# DMM register map
Vendor: Texas Instruments
Peripheral module from a debugger description file (folder am574x).
Registers are 32-bit, access not given, reset values left out (the file's numbers can be read two ways) unless marked. A register's access mark holds for its fields unless they carry their own. Offsets are as the file gives them; lines under a group give offsets from that group; [hi:lo] are bit positions; {n}, {i} and the like mark numbered series; 'fields as' and 'values as' point back to an identical list; <NAME> marks a mode.

## DMM
0x00 DMM_REVISION ro — DMM revision number
  [31:0] REVISION — Revision number
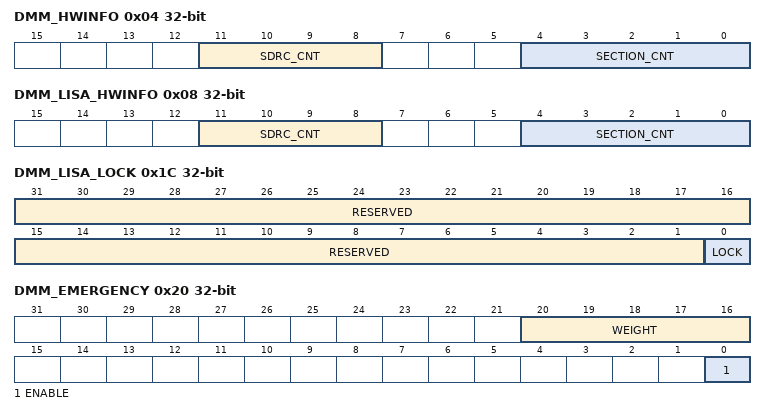
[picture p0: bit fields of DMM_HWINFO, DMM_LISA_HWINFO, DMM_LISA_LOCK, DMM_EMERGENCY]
0x04 DMM_HWINFO ro — DMM hardware configuration
  [11:8] SDRC_CNT — Number of attached SDRAM controllers
  [4:0] SECTION_CNT — Number of DMM sections
0x08 DMM_LISA_HWINFO ro — DMM hardware configuration for LISA
  fields as DMM_HWINFO
0x10 DMM_SYSCONFIG — DMM clock management configuration
  [3:2] IDLE_MODE rw — Configuration of the local target state management mode.
    0=FORCE_IDLE (Force-idle mode: local target's idle state follows (acknowledges) the system's idle requests unconditionally, that is, regardless of the IP module's internal requirements. Backup mode, for debug only.); 1=NO_IDLE (No-idle mode: local target never enters idle state. Backup mode, for debug only.); 2=SMART (Smart-idle mode: local target's idle state eventually follows (acknowledges) the system's idle requests, depending on the IP module's internal requirements. IP module shall not generate (IRQ- or DMA-request-related) wake-up events.)
0x1C DMM_LISA_LOCK access per field — DMM memory mapping lock
  [31:1] RESERVED ro — Should be written as 0
  [0] LOCK rw — DMM lock map
    0=UNLOCKED (No effect (clear on reset only)); 0=UNLOCKED; 1=LOCKED; 1=LOCKED (Locking registers)
0x20 DMM_EMERGENCY access per field — DMM memory mapping register
  [20:16] WEIGHT rw — Weight for the LISA arbitration when any bit of the vector Mflag[63:0] is set.The recommendation is to set this field to 0x8 with ENABLE =1, after reset. .
  [0] ENABLE rw — 0: Emergency feature is disabled.The recommendation is to enable the feature (=1) after reset. enum=UNLOCKED .
    1=UNLOCKED (Enable the emergency feature. LISA arbitration priority is higher for the initiator that set Mflag input of this initiator.)
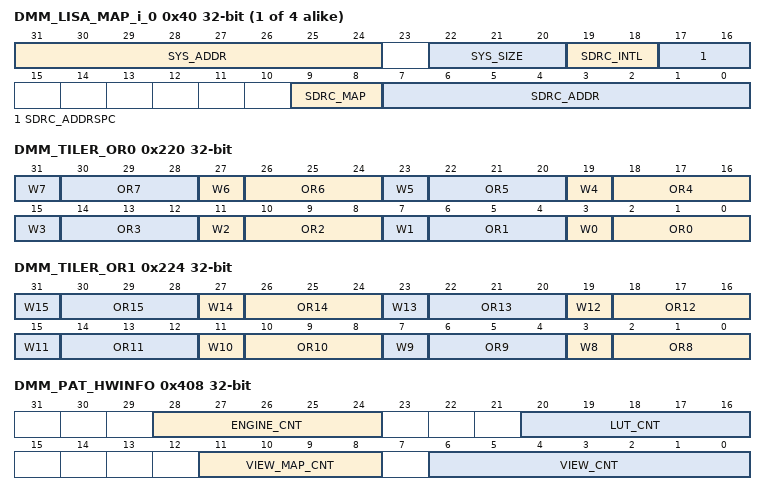
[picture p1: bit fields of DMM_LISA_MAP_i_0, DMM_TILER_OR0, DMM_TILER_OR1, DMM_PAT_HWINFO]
{0x40+4i} DMM_LISA_MAP_i_{i} (i=0..3) — DMM memory mapping register
  [31:24] SYS_ADDR rw — DMM system section address MSB for view mapping i
  [22:20] SYS_SIZE rw — DMM system section size for view mapping i
    0=16-MiB_section; 1=32-MiB_section; 2=64-MiB_section; 3=128-MiB_section; 4=256-MiB_section; 5=512-MiB_section; 6=1-GiB_section; 7=2-GiB_section
  [19:18] SDRC_INTL rw — SDRAM controller interleaving mode 0x0: No interleaving 0x1: 128-byte interleaving 0x2: 256-byte interleaving 0x3: 512-byte interleaving The 128-/256-/512-byte interleaving applies only to nontiled regions. If accesses are made to tiled regions, interleaving is forced to 1kiB. SDRC_INTL is don't care if SDRC_MAP is not 0x3 (no interleaving).
  [17:16] SDRC_ADDRSPC rw — SDRAM controller address space for view mapping i
  [9:8] SDRC_MAP rw — SDRAM controller mapping for view mapping i 0x0: Unmapped 0x1: Mapped on EMIF1 only (not interleaved) 0x2: Mapped on EMIF2 only (not interleaved) 0x3: Mapped on EMIF1 and EMIF2 (interleaved) To enable interleaving, SDRC_MAP must be 0x3 and SDRC_INTL must be a nonzero value.
  [7:0] SDRC_ADDR rw — SDRAM controller address MSB for view mapping i
0x208 DMM_TILER_HWINFO ro — DMM hardware configuration for TILER
  [6:0] OR_CNT — Number of TILER orientation entries
    4=OR_CNT_4_r (Four orientation entries); 32=OR_CNT_32_r (Thirty-two orientation entries); 64=OR_CNT_64_r (Sixty-four orientation entries); 2=OR_CNT_2_r (Two orientation entries); 1=OR_CNT_1_r (One orientation entry); 8=OR_CNT_8_r (Eight orientation entries); 16=OR_CNT_16_r (Sixteen orientation entries)
0x220 DMM_TILER_OR0 rw — DMM TILER orientation (initiators 0 to 7)
  [4n+3] W{n} (n=0..7) — Write-enable for OR{n} bit field
    0=OR{n}_field_is_unchanged; 1=OR{n}_field_is_updated
  [4n+2:4n] OR{n} (n=0..7) — Orientation for initiator {n}
0x224 DMM_TILER_OR1 rw — DMM TILER orientation (initiators 8 to 15)
  [4n-29] W{n} (n=8..15) — Write-enable for OR{n} bit field
    0=OR{n}_field_is_unchanged; 1=OR{n}_field_is_updated
  [4n-30:4n-32] OR{n} (n=8..15) — Orientation for initiator {n}
0x408 DMM_PAT_HWINFO ro — DMM hardware configuration for PAT
  [28:24] ENGINE_CNT — Number of PAT refill engines
  [20:16] LUT_CNT — Number of PAT LUT for page-grained physical address translation
  [11:8] VIEW_MAP_CNT — Number of internal PAT view mappings.
    1=VIEW_MAP_CNT_1_r (One view map); 2=VIEW_MAP_CNT_2_r (Two view maps); 4=VIEW_MAP_CNT_4_r (Four view maps); 8=VIEW_MAP_CNT_8_r (Eight view maps)
  [6:0] VIEW_CNT — Number of PAT view entries
    1=VIEW_CNT_1_r (One view entry); 2=VIEW_CNT_2_r (Two view entries); 4=VIEW_CNT_4_r (Four view entries); 8=VIEW_CNT_8_r (Eight view entries); 16=VIEW_CNT_16_r (Sixteen view entries); 32=VIEW_CNT_32_r (Thirty-two view entries); 64=VIEW_CNT_64_r (Sixty-four view entries)
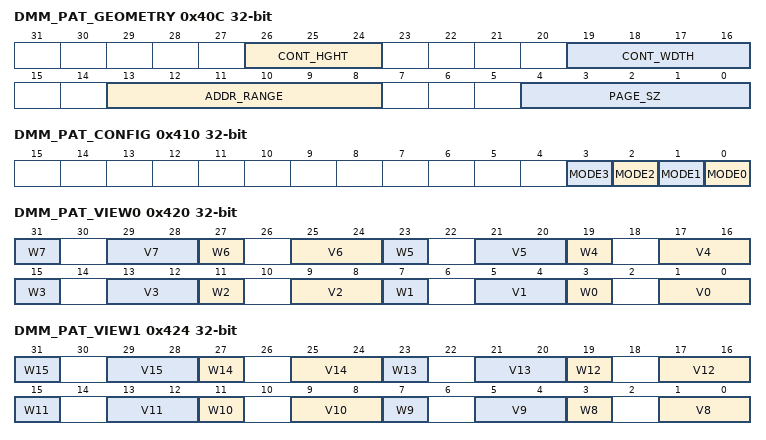
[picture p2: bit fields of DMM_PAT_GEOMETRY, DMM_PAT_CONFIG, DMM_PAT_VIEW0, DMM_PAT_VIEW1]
0x40C DMM_PAT_GEOMETRY ro — PAT geometry-related settings
  [26:24] CONT_HGHT — Container height in pages
  [19:16] CONT_WDTH — Container width in pages
    2=CONT_WDTH_2_r (Container width of 64 pages); 4=CONT_WDTH_4_r (Container width of 128 pages); 8=CONT_WDTH_8_r (Container width of 256 pages)
  [13:8] ADDR_RANGE — PAT output physical address range
    1=128MB (128-MiB range); 2=256MB (256-MiB range); 4=512MB (512-MiB range); 8=1GB (1-GiB range); 16=2GB (2-GiB range); 32=4GB (4-GiB range)
  [4:0] PAGE_SZ — Page size in 4-kiB granularity
    1=4KB (4-kiB page); 4=16KB (16-kiB page); 16=64KB (64-kiB page)
0x410 DMM_PAT_CONFIG access per field — This is the PAT configuration register aimed at defining the major PAT configuration of each refill engine.
  [all] fields
    0=PROG (Normal mode); 1=BYPASS (Direct LUT access)
  [n] MODE{n} rw (n=0..3) — Mode of refill engine {n}
0x420 DMM_PAT_VIEW0 — DMM PAT View register (initiators 0 to 7)
  [4n+3] W{n} rw (n=0..7) — Write-enable for V{n} bit field
    0=V{n}_field_is_unchanged; 1=V{n}_field_is_updated
  [4n+1:4n] V{n} rw (n=0..7) — PAT view for initiator {n}
0x424 DMM_PAT_VIEW1 — DMM PAT view register (initiators 8 to 15)
  [4n-29] W{n} rw (n=8..15) — Write-enable for V{n} bit field
    0=V{n}_field_is_unchanged; 1=V{n}_field_is_updated
  [4n-31:4n-32] V{n} rw (n=8..15) — PAT view for initiator {n}
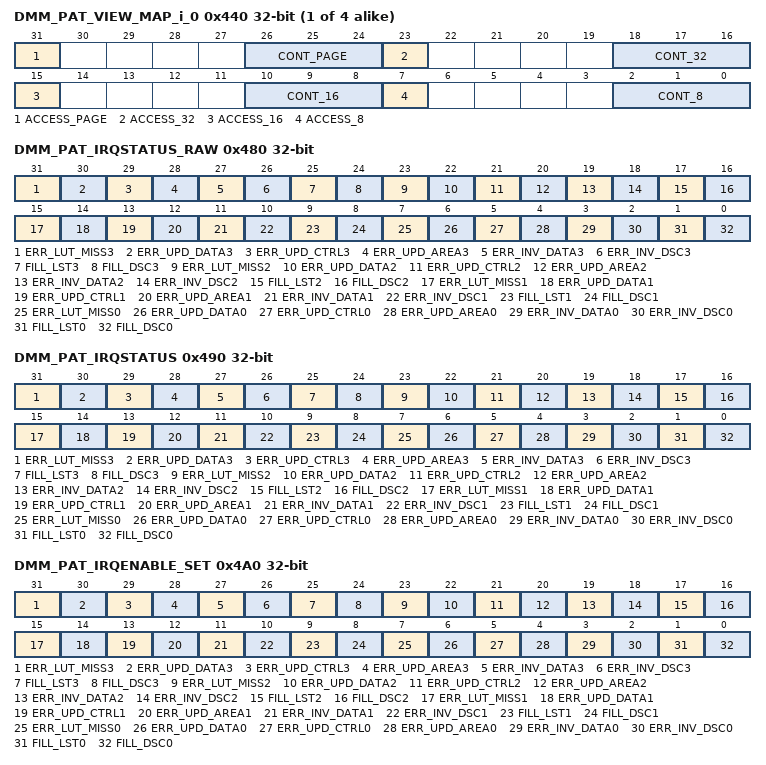
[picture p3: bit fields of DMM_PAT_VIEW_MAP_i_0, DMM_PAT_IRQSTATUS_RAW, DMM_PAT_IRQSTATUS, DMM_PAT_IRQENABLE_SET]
{0x440+4i} DMM_PAT_VIEW_MAP_i_{i} (i=0..3) — PAT view mapping register
  [31] ACCESS_PAGE rw — Kind of access for this page mode container in view mapping i
    0=DIRECT (Direct access, container base address given in CONT_PAGE); 1=LUT (indirect access through the LUT indexed by CONT_PAGE)
  [26:24] CONT_PAGE rw — Container for page mode in view mapping i
  [23] ACCESS_32 rw — Kind of access for this 32-bit mode container in view mapping i
    0=DIRECT (Direct access, container base address given in CONT_32); 1=LUT (indirect access through the LUT indexed by CONT_32)
  [18:16] CONT_32 rw — Container for 32-bit mode in view mapping i
  [15] ACCESS_16 rw — Kind of access for this 16-bit mode container in view mapping i
    0=DIRECT (Direct access, container base address given in CONT_16); 1=LUT (indirect access through the LUT indexed by CONT_16)
  [10:8] CONT_16 rw — Container for 16-bit mode in view mapping i
  [7] ACCESS_8 rw — Kind of access for this 8-bit mode container in view mapping i
    0=DIRECT (Direct access, container base address given in CONT_8); 1=LUT (indirect access through the LUT indexed by CONT_8)
  [2:0] CONT_8 rw — Container for 8-bit mode in view mapping i
0x460 DMM_PAT_VIEW_MAP_BASE — Base address of all view mappings
  [31] BASE_ADDR rw — MSB of the PAT view mapping base address
0x478 DMM_PAT_IRQ_EOI access per field — PAT end of interrupt
  [0] EOI rw — End of PAT interrupt
    0=ACK (Acknowledge the PAT interrupts)
0x480 DMM_PAT_IRQSTATUS_RAW — Per-event raw interrupt status vector. Raw status is set even if the related event is not enabled. Write 1 to set the (raw) status, mostly for debug. n = 0 for the first interrupt status raw register, n = 1 for the second interrupt status raw register.
  [31] ERR_LUT_MISS3 — Access to a yet-to-be-refilled area event in area 4.n+3 (access RW W1toSet)
    0=KEEP (Keep current error event.); 1=SET (Set error event.); 1=HAPPEN (Error event happened.); 0=NONE (No such error event)
  [30] ERR_UPD_DATA3 — Data register update whilst refilling error event in area 4.n+3 (access RW W1toSet)
    values as ERR_LUT_MISS3
  [29] ERR_UPD_CTRL3 — Control register update whilst refilling error event in area 4.n+3 (access RW W1toSet)
    values as ERR_LUT_MISS3
  [28] ERR_UPD_AREA3 — Area register update whilst refilling error event in area 4.n+3 (access RW W1toSet)
    values as ERR_LUT_MISS3
  [27] ERR_INV_DATA3 — Invalid entry-table pointer error event in area 4.n+3 (access RW W1toSet)
    0=KEEP (Keep current error event.); 1=SET (Set error event.); 1=HAPPEN (Error event happened.); 0=NONE (No such error event.)
  [26] ERR_INV_DSC3 — Invalid descriptor pointer error event in area 4.n+3 (access RW W1toSet)
    values as ERR_LUT_MISS3
  [25] FILL_LST3 — End of refill event for the last descriptor in area 4.n+3 (access RW W1toSet)
    0=KEEP (Keep area 3 refill done event.); 1=SET (Set area 3 refill done event.); 1=DONE (Area 3 is refilled.); 0=NOT (Area 3 is yet-to-be refilled.)
  [24] FILL_DSC3 — End of refill event for any descriptor in area 4.n+3 (access RW W1toSet)
    values as FILL_LST3
  [23] ERR_LUT_MISS2 — Access to a yet-to-be-refilled area event in area 4.n+2 (access RW W1toSet)
    values as ERR_LUT_MISS3
  [22] ERR_UPD_DATA2 — Data register update whilst refilling error event in area 4.n+2 (access RW W1toSet)
    values as ERR_LUT_MISS3
  [21] ERR_UPD_CTRL2 — Control register update whilst refilling error event in area 4.n+2 (access RW W1toSet)
    values as ERR_LUT_MISS3
  [20] ERR_UPD_AREA2 — Area register update whilst refilling error event in area 4.n+2 (access RW W1toSet)
    values as ERR_LUT_MISS3
  [19] ERR_INV_DATA2 — Invalid entry-table pointer error event in area 4.n+2 (access RW W1toSet)
    values as ERR_LUT_MISS3
  [18] ERR_INV_DSC2 — Invalid descriptor pointer error event in area 4.n+2 (access RW W1toSet)
    values as ERR_LUT_MISS3
  [17] FILL_LST2 — End of refill event for the last descriptor in area 4.n+2 (access RW W1toSet)
    0=KEEP (Keep area 2 refill done event.); 1=SET (Set area 2 refill done event.); 1=DONE (Area 2 is refilled.); 0=NOT (Area 2 is yet-to-be refilled.)
  [16] FILL_DSC2 — End of refill event for any descriptor in area 4.n+2 (access RW W1toSet)
    values as FILL_LST2
  [15] ERR_LUT_MISS1 — Access to a yet-to-be-refilled area event in area 4.n+1 (access RW W1toSet)
    values as ERR_LUT_MISS3
  [14] ERR_UPD_DATA1 — Data register update whilst refilling error event in area 4.n+1 (access RW W1toSet)
    values as ERR_LUT_MISS3
  [13] ERR_UPD_CTRL1 — Control register update whilst refilling error event in area 4.n+1 (access RW W1toSet)
    values as ERR_LUT_MISS3
  [12] ERR_UPD_AREA1 — Area register update whilst refilling error event in area 4.n+1 (access RW W1toSet)
    values as ERR_LUT_MISS3
  [11] ERR_INV_DATA1 — Invalid entry-table pointer error event in area 4.n+1 (access RW W1toSet)
    values as ERR_LUT_MISS3
  [10] ERR_INV_DSC1 — Invalid descriptor pointer error event in area 4.n+1 (access RW W1toSet)
    values as ERR_LUT_MISS3
  [9] FILL_LST1 — End of refill event for the last descriptor in area 4.n+1 (access RW W1toSet)
    0=KEEP (Keep area 1 refill done event.); 1=SET (Set area 1 refill done event.); 1=DONE (Area 1 is refilled.); 0=NOT (Area 1 is yet-to-be refilled.)
  [8] FILL_DSC1 — End of refill event for any descriptor in area 4.n+1 (access RW W1toSet)
    values as FILL_LST1
  [7] ERR_LUT_MISS0 — Access to a yet-to-be-refilled area event in area 4.n (access RW W1toSet)
    values as ERR_LUT_MISS3
  [6] ERR_UPD_DATA0 — Data register update whilst refilling error event in area 4.n (access RW W1toSet)
    values as ERR_LUT_MISS3
  [5] ERR_UPD_CTRL0 — Control register update whilst refilling error event in area 4.n (access RW W1toSet)
    values as ERR_LUT_MISS3
  [4] ERR_UPD_AREA0 — Area register update whilst refilling error event in area 4.n (access RW W1toSet)
    values as ERR_LUT_MISS3
  [3] ERR_INV_DATA0 — Invalid entry-table pointer error event in area 4.n (access RW W1toSet)
    values as ERR_LUT_MISS3
  [2] ERR_INV_DSC0 — Invalid descriptor pointer error event in area 4.n (access RW W1toSet)
    values as ERR_LUT_MISS3
  [1] FILL_LST0 — End of refill event for the last descriptor in area 4.n (access RW W1toSet)
    0=KEEP (Keep area 0 refill done event.); 1=SET (Set area 0 refill done event.); 1=DONE (Area 0 is refilled.); 0=NOT (Area 0 is yet-to-be refilled.)
  [0] FILL_DSC0 — End of refill event for any descriptor in area 4.n (access RW W1toSet)
    values as FILL_LST0
0x490 DMM_PAT_IRQSTATUS — Per-event 'enabled' interrupt status vector. Enabled status is not set unless the event is enabled. Write 1 to clear the status after interrupt has been serviced (raw status gets cleared, that is, even if not enabled). n = 0 for the first interrupt status register, n = 1 for the second interrupt status register.
  [31] ERR_LUT_MISS3 — Access to a yet-to-be-refilled area event in area 4.n+3 (access RW W1toClr)
    0=KEEP (Keep current maskable error event.); 1=CLR (Clear this maskable error event.); 1=HAPPEN (Error event happened.); 0=NONE (No such error event or this event is masked.)
  [30] ERR_UPD_DATA3 — Data register update whilst refilling error event in area 4.n+3 (access RW W1toClr)
    values as ERR_LUT_MISS3
  [29] ERR_UPD_CTRL3 — Control register update whilst refilling error event in area 4.n+3 (access RW W1toClr)
    values as ERR_LUT_MISS3
  [28] ERR_UPD_AREA3 — Area register update whilst refilling error event in area 4.n+3 (access RW W1toClr)
    values as ERR_LUT_MISS3
  [27] ERR_INV_DATA3 — Invalid entry-table pointer error event in area 4.n+3 (access RW W1toClr)
    values as ERR_LUT_MISS3
  [26] ERR_INV_DSC3 — Invalid descriptor pointer error event in area 4.n+3 (access RW W1toClr)
    values as ERR_LUT_MISS3
  [25] FILL_LST3 — End of refill event for the last descriptor in area 4.n+3 (access RW W1toClr)
    0=KEEP (Keep current area refill done maskable event.); 1=CLR (Clear current area refill done maskable event.); 1=DONE (Current area is refilled.); 0=NOT (Current area is yet-to-be refilled or this event is masked.)
  [24] FILL_DSC3 — End of refill event for any descriptor in area 4.n+3 (access RW W1toClr)
    values as FILL_LST3
  [23] ERR_LUT_MISS2 — Access to a yet-to-be-refilled area event in area 4.n+2 (access RW W1toClr)
    values as ERR_LUT_MISS3
  [22] ERR_UPD_DATA2 — Data register update whilst refilling error event in area 2 (access RW W1toClr)
    values as ERR_LUT_MISS3
  [21] ERR_UPD_CTRL2 — Control register update whilst refilling error event in area 4.n+2 (access RW W1toClr)
    values as ERR_LUT_MISS3
  [20] ERR_UPD_AREA2 — Area register update whilst refilling error event in area 4.n+2 (access RW W1toClr)
    values as ERR_LUT_MISS3
  [19] ERR_INV_DATA2 — Invalid entry-table pointer error event in area 4.n+2 (access RW W1toClr)
    values as ERR_LUT_MISS3
  [18] ERR_INV_DSC2 — Invalid descriptor pointer error event in area 4.n+2 (access RW W1toClr)
    values as ERR_LUT_MISS3
  [17] FILL_LST2 — End of refill event for the last descriptor in area 4.n+2 (access RW W1toClr)
    values as FILL_LST3
  [16] FILL_DSC2 — End of refill event for any descriptor in area 4.n+2 (access RW W1toClr)
    values as FILL_LST3
  [15] ERR_LUT_MISS1 — Access to a yet-to-be-refilled area event in area 4.n+1 (access RW W1toClr)
    values as ERR_LUT_MISS3
  [14] ERR_UPD_DATA1 — Data register update whilst refilling error event in area 4.n+1 (access RW W1toClr)
    values as ERR_LUT_MISS3
  [13] ERR_UPD_CTRL1 — Control register update whilst refilling error event in area 4.n+1 (access RW W1toClr)
    values as ERR_LUT_MISS3
  [12] ERR_UPD_AREA1 — Area register update whilst refilling error event in area 4.n+1 (access RW W1toClr)
    values as ERR_LUT_MISS3
  [11] ERR_INV_DATA1 — Invalid entry-table pointer error event in area 4.n+1 (access RW W1toClr)
    0=KEEP (Keep current maskable error event.); 1=CLR (Clear this maskable error event.); 1=HAPPEN (Error event happened.); 0=NONE (No such error event or this event is masked)
  [10] ERR_INV_DSC1 — Invalid descriptor pointer error event in area 4.n+1 (access RW W1toClr)
    values as ERR_INV_DATA1
  [9] FILL_LST1 — End of refill event for the last descriptor in area 4.n+1 (access RW W1toClr)
    values as FILL_LST3
  [8] FILL_DSC1 — End of refill event for any descriptor in area 4.n+1 (access RW W1toClr)
    values as FILL_LST3
  [7] ERR_LUT_MISS0 — Access to a yet-to-be-refilled area event in area 4.n (access RW W1toClr)
    values as ERR_LUT_MISS3
  [6] ERR_UPD_DATA0 — Data register update whilst refilling error event in area 4.n (access RW W1toClr)
    values as ERR_LUT_MISS3
  [5] ERR_UPD_CTRL0 — Control register update whilst refilling error event in area 4.n (access RW W1toClr)
    values as ERR_LUT_MISS3
  [4] ERR_UPD_AREA0 — Area register update whilst refilling error event in area 4.n (access RW W1toClr)
    values as ERR_LUT_MISS3
  [3] ERR_INV_DATA0 — Invalid entry-table pointer error event in area 4.n (access RW W1toClr)
    values as ERR_LUT_MISS3
  [2] ERR_INV_DSC0 — Invalid descriptor pointer error event in area 4.n (access RW W1toClr)
    values as ERR_LUT_MISS3
  [1] FILL_LST0 — End of refill event for the last descriptor in area 4.n (access RW W1toClr)
    values as FILL_LST3
  [0] FILL_DSC0 — End of refill event for any descriptor in area 4.n (access RW W1toClr)
    values as FILL_LST3
0x4A0 DMM_PAT_IRQENABLE_SET — Per-event interrupt enable bit vector. Write 1 to set (enable interrupt). Readout equal to corresponding _CLR register. n = 0 for the first interrupt enable set register, n = 1 for the second interrupt enable set register.
  [all] fields
    0=KEEP (Keep current mask of this interrupt source.); 1=ENABLE (Enable (unmask) this interrupt source.); 1=ENABLED (This interrupt source is enabled (unmasked).); 0=DISABLED (This interrupt source is disabled (masked).)
  [31] ERR_LUT_MISS3 — Unexpected access to a yet-to-be-refilled area interrupt source mask for area 4.n+3 (access RW W1toSet)
  [30] ERR_UPD_DATA3 — Unexpected data register update whilst refilling interrupt source mask for area 4.n+3 (access RW W1toSet)
  [29] ERR_UPD_CTRL3 — Unexpected control register update whilst refilling interrupt source mask for area 4.n+3 (access RW W1toSet)
  [28] ERR_UPD_AREA3 — Unexpected area register update whilst refilling interrupt source mask for area 4.n+3 (access RW W1toSet)
  [27] ERR_INV_DATA3 — Invalid entry-table pointer interrupt source mask for area 4.n+3 (access RW W1toSet)
  [26] ERR_INV_DSC3 — Invalid descriptor pointer interrupt source mask for area 4.n+3 (access RW W1toSet)
  [25] FILL_LST3 — End of refill interrupt source mask for the last descriptior in area 4.n+3 (access RW W1toSet)
  [24] FILL_DSC3 — End of refill interrupt source mask for any descriptior in area 4.n+3 (access RW W1toSet)
  [23] ERR_LUT_MISS2 — Unexpected access to a yet-to-be-refilled area interrupt source mask for area 4.n+2 (access RW W1toSet)
  [22] ERR_UPD_DATA2 — Unexpected data register update whilst refilling interrupt source mask for area 4.n+2 (access RW W1toSet)
  [21] ERR_UPD_CTRL2 — Unexpected control register update whilst refilling interrupt source mask for area 4.n+2 (access RW W1toSet)
  [20] ERR_UPD_AREA2 — Unexpected area register update whilst refilling interrupt source mask for area 4.n+2 (access RW W1toSet)
  [19] ERR_INV_DATA2 — Invalid entry-table pointer interrupt source mask for area 4.n+2 (access RW W1toSet)
  [18] ERR_INV_DSC2 — Invalid descriptor pointer interrupt source mask for area 4.n+2 (access RW W1toSet)
  [17] FILL_LST2 — End of refill interrupt source mask for the last descriptior in area 4.n+2 (access RW W1toSet)
  [16] FILL_DSC2 — End of refill interrupt source mask for any descriptior in area 4.n+2 (access RW W1toSet)
  [15] ERR_LUT_MISS1 — Unexpected access to a yet-to-be-refilled area interrupt source mask for area 4.n+1 (access RW W1toSet)
  [14] ERR_UPD_DATA1 — Unexpected data register update whilst refilling interrupt source mask for area 4.n+1 (access RW W1toSet)
  [13] ERR_UPD_CTRL1 — Unexpected control register update whilst refilling interrupt source mask for area 4.n+1 (access RW W1toSet)
  [12] ERR_UPD_AREA1 — Unexpected area register update whilst refilling interrupt source mask for area 4.n+1 (access RW W1toSet)
  [11] ERR_INV_DATA1 — Invalid entry-table pointer interrupt source mask for area 4.n+1 (access RW W1toSet)
  [10] ERR_INV_DSC1 — Invalid descriptor pointer interrupt source mask for area 4.n+1 (access RW W1toSet)
  [9] FILL_LST1 — End of refill interrupt source mask for the last descriptior in area 4.n+1 (access RW W1toSet)
  [8] FILL_DSC1 — End of refill interrupt source mask for any descriptior in area 4.n+1 (access RW W1toSet)
  [7] ERR_LUT_MISS0 — Unexpected access to a yet-to-be-refilled area interrupt source mask for area 4.n (access RW W1toSet)
  [6] ERR_UPD_DATA0 — Unexpected data register update whilst refilling interrupt source mask for area 4.n (access RW W1toSet)
  [5] ERR_UPD_CTRL0 — Unexpected control register update whilst refilling interrupt source mask for area 4.n (access RW W1toSet)
  [4] ERR_UPD_AREA0 — Unexpected area register update whilst refilling interrupt source mask for area 4.n (access RW W1toSet)
  [3] ERR_INV_DATA0 — Invalid entry-table pointer interrupt source mask for area 4.n (access RW W1toSet)
  [2] ERR_INV_DSC0 — Invalid descriptor pointer interrupt source mask for area 4.n (access RW W1toSet)
  [1] FILL_LST0 — End of refill interrupt source mask for the last descriptior in area 4.n (access RW W1toSet)
  [0] FILL_DSC0 — End of refill interrupt source mask for any descriptior in area 4.n (access RW W1toSet)
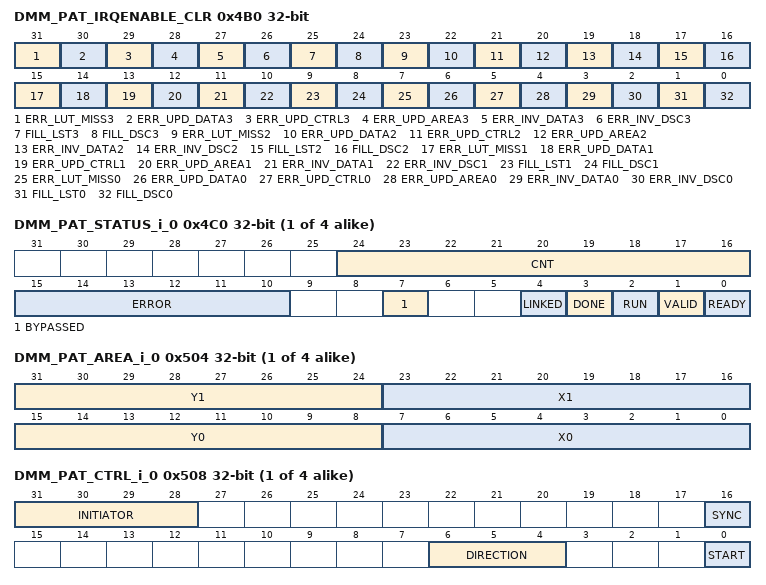
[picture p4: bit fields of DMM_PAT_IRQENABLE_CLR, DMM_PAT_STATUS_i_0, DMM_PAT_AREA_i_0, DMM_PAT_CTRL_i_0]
0x4B0 DMM_PAT_IRQENABLE_CLR — Per-event interrupt enable bit vector. Write 1 to clear (disable interrupt). Readout equal to corresponding _SET register. n = 0 for the first interrupt enable clear register, n = 1 for the second interrupt enable clear register.
  [31] ERR_LUT_MISS3 — Unexpected access to a yet-to-be-refilled area interrupt source mask for area 4.n+3 (access RW W1toClr)
    0=KEEP (Keep current mask of this interrupt source.); 1=DISABLE (Disable (mask) this interrupt source.); 1=ENABLED (This interrupt source is enabled (unmasked).); 0=DISABLED (This interrupt source is disabled (masked).)
  [30] ERR_UPD_DATA3 — Unexpected data register update whilst refilling interrupt source mask for area 4.n+3 (access RW W1toClr)
    values as ERR_LUT_MISS3
  [29] ERR_UPD_CTRL3 — Unexpected control register update whilst refilling interrupt source mask for area 4.n+3 (access RW W1toClr)
    values as ERR_LUT_MISS3
  [28] ERR_UPD_AREA3 — Unexpected area register update whilst refilling interrupt source mask for area 4.n+3 (access RW W1toClr)
    values as ERR_LUT_MISS3
  [27] ERR_INV_DATA3 — Invalid entry-table pointer interrupt source mask for area 4.n+3 (access RW W1toClr)
    values as ERR_LUT_MISS3
  [26] ERR_INV_DSC3 — Invalid descriptor pointer interrupt source mask for area 4.n+3 (access RW W1toClr)
    values as ERR_LUT_MISS3
  [25] FILL_LST3 — End of refill interrupt source mask for the last descriptior in area 4.n+3 (access RW W1toClr)
    0=KEEP (Keep current mask of this interrupt source.); 1=DISABLE (Disable (mask) this interrupt source.); 1=ENABLED (This interrupt source is enabled (unmasked)..); 0=DISABLED (This interrupt source is disabled (masked).)
  [24] FILL_DSC3 — End of refill interrupt source mask for any descriptior in area 4.n+3 (access RW W1toClr)
    values as ERR_LUT_MISS3
  [23] ERR_LUT_MISS2 — Unexpected access to a yet-to-be-refilled area interrupt source mask for area 4.n+2 (access RW W1toClr)
    values as ERR_LUT_MISS3
  [22] ERR_UPD_DATA2 — Unexpected data register update whilst refilling interrupt source mask for area 4.n+2 (access RW W1toClr)
    values as ERR_LUT_MISS3
  [21] ERR_UPD_CTRL2 — Unexpected control register update whilst refilling interrupt source mask for area 4.n+2 (access RW W1toClr)
    values as ERR_LUT_MISS3
  [20] ERR_UPD_AREA2 — Unexpected area register update whilst refilling interrupt source mask for area 4.n+2 (access RW W1toClr)
    values as ERR_LUT_MISS3
  [19] ERR_INV_DATA2 — Invalid entry-table pointer interrupt source mask for area 4.n+2 (access RW W1toClr)
    values as ERR_LUT_MISS3
  [18] ERR_INV_DSC2 — Invalid descriptor pointer interrupt source mask for area 4.n+2 (access RW W1toClr)
    values as ERR_LUT_MISS3
  [17] FILL_LST2 — End of refill interrupt source mask for the last descriptior in area 4.n+2 (access RW W1toClr)
    values as ERR_LUT_MISS3
  [16] FILL_DSC2 — End of refill interrupt source mask for any descriptior in area 4.n+2 (access RW W1toClr)
    values as ERR_LUT_MISS3
  [15] ERR_LUT_MISS1 — Unexpected access to a yet-to-be-refilled area interrupt source mask for area 4.n+1 (access RW W1toClr)
    values as ERR_LUT_MISS3
  [14] ERR_UPD_DATA1 — Unexpected data register update whilst refilling interrupt source mask for area 4.n+1 (access RW W1toClr)
    values as ERR_LUT_MISS3
  [13] ERR_UPD_CTRL1 — Unexpected control register update whilst refilling interrupt source mask for area 4.n+1 (access RW W1toClr)
    values as ERR_LUT_MISS3
  [12] ERR_UPD_AREA1 — Unexpected area register update whilst refilling interrupt source mask for area 4.n+1 (access RW W1toClr)
    values as ERR_LUT_MISS3
  [11] ERR_INV_DATA1 — Invalid entry-table pointer interrupt source mask for area 4.n+1 (access RW W1toClr)
    values as ERR_LUT_MISS3
  [10] ERR_INV_DSC1 — Invalid descriptor pointer interrupt source mask for area 4.n+1 (access RW W1toClr)
    values as ERR_LUT_MISS3
  [9] FILL_LST1 — End of refill interrupt source mask for the last descriptior in area 4.n+1 (access RW W1toClr)
    values as ERR_LUT_MISS3
  [8] FILL_DSC1 — End of refill interrupt source mask for any descriptior in area 4.n+1 (access RW W1toClr)
    values as ERR_LUT_MISS3
  [7] ERR_LUT_MISS0 — Unexpected access to a yet-to-be-refilled area interrupt source mask for area 4.n (access RW W1toClr)
    values as ERR_LUT_MISS3
  [6] ERR_UPD_DATA0 — Unexpected data register update whilst refilling interrupt source mask for area 4.n (access RW W1toClr)
    values as ERR_LUT_MISS3
  [5] ERR_UPD_CTRL0 — Unexpected control register update whilst refilling interrupt source mask for area 4.n (access RW W1toClr)
    values as ERR_LUT_MISS3
  [4] ERR_UPD_AREA0 — Unexpected area register update whilst refilling interrupt source mask for area 4.n (access RW W1toClr)
    values as ERR_LUT_MISS3
  [3] ERR_INV_DATA0 — Invalid entry-table pointer interrupt source mask for area 4.n (access RW W1toClr)
    values as ERR_LUT_MISS3
  [2] ERR_INV_DSC0 — Invalid descriptor pointer interrupt source mask for area 4.n (access RW W1toClr)
    values as ERR_LUT_MISS3
  [1] FILL_LST0 — End of refill interrupt source mask for the last descriptior in area 4.n (access RW W1toClr)
    values as ERR_LUT_MISS3
  [0] FILL_DSC0 — End of refill interrupt source mask for any descriptior in area 4.n (access RW W1toClr)
    values as ERR_LUT_MISS3
{0x4C0+4i} DMM_PAT_STATUS_i_{i} ro (i=0..3) — Status register for each refill engine n = 0 for the first engine status register, n = 1 for the second engine status register.
  [24:16] CNT — Counter of remaining lines to reload for engine n
  [15:10] ERROR — Error happened in engine n
    0=No_error; 1=Invalid_descriptor_provided; 2=Invalid_data_pointer_provided; 4=ERROR_4_r (Unexpected area register update while refilling); 8=ERROR_8_r (Unexpected control register update while refilling); 16=ERROR_16_r (Unexpected data register update while refilling); 32=ERROR_32_r (Unexpected access to a yet-to-be-refilled location)
  [7] BYPASSED — Engine n is bypassed. Direct access to the LUT is provided.
  [4] LINKED — Area reconfiguration link asserted for engine n
  [3] DONE — Area reloading finished for engine n
  [2] RUN — Area currently reloading for engine n
  [1] VALID — Valid area description for engine n
  [0] READY — Area registers ready for engine n
{0x500+0x10*i} DMM_PAT_DESCR_i_{i} (i=0..3) — Physical address of the next table refill descriptor n = 0 for the descriptor register of the first engine, n = 1 for the descriptor register of the second engine. Writing to this register aborts the current ongoing area reload and resets the corresponding, and registers.
  [31:4] ADDR — Physical address of the next table refill descriptor of engine n (access RW WtoClr)
{0x504+0x10*i} DMM_PAT_AREA_i_{i} rw (i=0..3) — Area definition for DMM physical address translator n = 0 for the area register of the first engine, n = 1 for the area register of the second engine.
  [31:24] Y1 — Y-coordinate of the bottom-right corner of the PAT area for engine n
  [23:16] X1 — X-coordinate of the bottom-right corner of the PAT area for engine n
  [15:8] Y0 — Y-coordinate of the top-left corner of the PAT area for engine n
  [7:0] X0 — X-coordinate of the top-left corner of the PAT area for engine n
{0x508+0x10*i} DMM_PAT_CTRL_i_{i} (i=0..3) — DMM physical address translator control register n = 0 for the control register of the first engine, n = 1 for the control register of the second engine.
  [31:28] INITIATOR rw — DMM PAT initiator for synchronization in engine n
  [16] SYNC rw — DMM PAT table reload synchronization for engine n
    0=Not_synchronized; 1=Synchronized
  [6:4] DIRECTION rw — Direction of this PAT table refill for engine n
  [0] START rw — Starting a PAT table refill with engine n
{0x50C+0x10*i} DMM_PAT_DATA_i_{i} (i=0..3) — Physical address of the current table refill entry data n = 0 for the data register of the first engine, n = 1 for the data register of the second engine.
  [31:4] ADDR rw — Physical address of the current table refill entry data or single actual entry data when in manual mode for engine n
0x608 DMM_PEG_HWINFO ro — DMM hardware configuration for PEG
  [6:0] PRIO_CNT — Number of PEG priority entries
    1=PRIO_CNT_1_r (One priority entry); 2=PRIO_CNT_2_r (Two priority entries); 4=PRIO_CNT_4_r (Four priority entries); 8=PRIO_CNT_8_r (Eight priority entries); 16=PRIO_CNT_16_r (Sixteen priority entries); 32=PRIO_CNT_32_r (Thirty-two priority entries); 64=PRIO_CNT_64_r (Sixty-four priority entries)
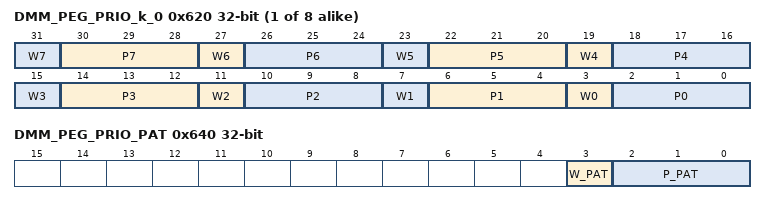
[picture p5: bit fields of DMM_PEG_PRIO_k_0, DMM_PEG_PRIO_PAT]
{0x620+4i} DMM_PEG_PRIO_k_{i} rw (i=0..7) — DMM PEG Priority register
  [4n+3] W{n} (n=0..7) — Write-enable for P{n} bit field
    0=KEEP (P{n} field is unchanged.); 1=UPDATE (P{n} field is updated.)
  [4n+2:4n] P{n} (n=1..7) — Priority for initiator ConnID = 8 × k + {n}
  [2:0] P0 — Priority for initiator ConnID = 8 × k
0x640 DMM_PEG_PRIO_PAT — DMM PEG priority register for the internal PAT engine.
  [3] W_PAT rw — Write-enable for P_PAT bit field
    0=UPDATE (P_PAT field is updated.); 1=KEEP (P_PAT field is unchanged.)
  [2:0] P_PAT rw — Priority for PAT engine
